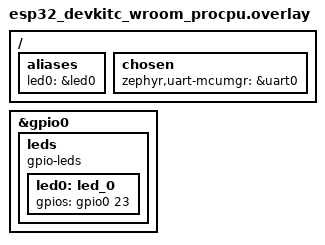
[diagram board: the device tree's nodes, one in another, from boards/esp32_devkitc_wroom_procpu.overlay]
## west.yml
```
manifest:
  projects:
    - name: zephyr
      url: https://github.com/zephyrproject-rtos/zephyr
      revision: v3.7.0
      west-commands: scripts/west-commands.yml
      import:
        # Limit the Zephyr modules to the required set
        name-allowlist:
          - hal_espressif
          - mbedtls
          - tinycrypt
          - mcuboot
          - zcbor
```

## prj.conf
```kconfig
 #Configure compatability with MCUBoot
CONFIG_BOOTLOADER_MCUBOOT=y

#Configure MCUmgr server
CONFIG_MCUMGR=y

#Configure MCUmgr dependencies
CONFIG_NET_BUF=y
CONFIG_ZCBOR=y

# Enable image command handlers for MCUmgr server
CONFIG_MCUMGR_GRP_IMG=y

# Configure dependencies for image command handlers
CONFIG_FLASH=y
CONFIG_IMG_MANAGER=y

#Configure dependencies for IMG_MANAGER symbol
CONFIG_STREAM_FLASH=y

#Configure dependencies for STREAM_FLASH symbol
CONFIG_FLASH_MAP=y

# Enable MCUmgr server to communicate over UART
CONFIG_MCUMGR_TRANSPORT_UART=y

# Configure dependencies for serial communication
CONFIG_CRC=y
CONFIG_BASE64=y
```

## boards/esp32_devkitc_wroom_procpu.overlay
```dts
/ {
    aliases {
        led0 = &led0;
    };
    chosen {
        zephyr,uart-mcumgr = &uart0;
    };
};

&gpio0 {
    leds: leds {
        compatible="gpio-leds";
        led0: led_0{
            gpios = <&gpio0 23 GPIO_ACTIVE_HIGH>;
        };
    };
};
```

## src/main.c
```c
#include <zephyr/kernel.h>
#include <zephyr/devicetree.h>
#include <zephyr/drivers/gpio.h>

#define SLEEP_TIME 2000U

struct gpio_dt_spec led0 = GPIO_DT_SPEC_GET(DT_ALIAS(led0), gpios);

int main(void){

	//Validate GPIO port is ready for use
	if(!gpio_is_ready_dt(&led0)){
		return 0;
	}

	//Configure GPIO port as an output
	gpio_pin_configure_dt(&led0, GPIO_OUTPUT_ACTIVE);

	//Continuously toggle LED, every ’SLEEP_TIME’ ms
	while(1){
		gpio_pin_toggle_dt(&led0);
		k_msleep(SLEEP_TIME);
	}
	return 0;
}
```
